# PIC16LF1509 register map
Vendor: Microchip
Registers are 8-bit, read-write, no defined reset value unless marked. A register's access mark holds for its fields unless they carry their own. Addresses are absolute, and some are shared; only a register's first bit layout is shown; [hi:lo] are bit positions; {n}, {i} and the like mark numbered series.

## SFR
0x00 INDF0 — (power-on value xxxxxxxx)
0x01 INDF1 — (power-on value xxxxxxxx)
0x02 PCL reset 0x0
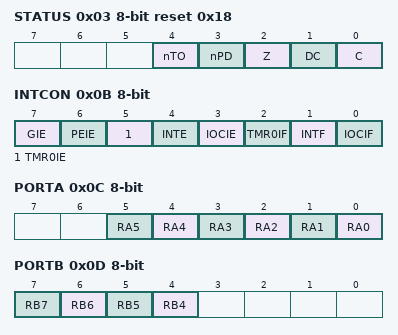
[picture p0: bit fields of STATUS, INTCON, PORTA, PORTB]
0x03 STATUS reset 0x18
  [4] nTO ro, [3] nPD ro, [2] Z, [1] DC, [0] C
0x04 FSR0L reset 0x0
0x05 FSR0H reset 0x0
0x06 FSR1L reset 0x0
0x07 FSR1H reset 0x0
0x08 BSR reset 0x0
  [4:0] BSR
0x09 WREG reset 0x0
  [7:0] WREG0
0x0A PCLATH reset 0x0
  [6:0] PCLATH
0x0B INTCON — (power-on value 0000000x)
  [7] GIE, [6] PEIE, [5] TMR0IE, [4] INTE, [3] IOCIE, [2] TMR0IF, [1] INTF, [0] IOCIF ro
0x0C PORTA — (power-on value --xxxxxx)
  [n] RA{n} (n=0..5)
0x0D PORTB — (power-on value xxxx----)
  [n] RB{n} (n=4..7)
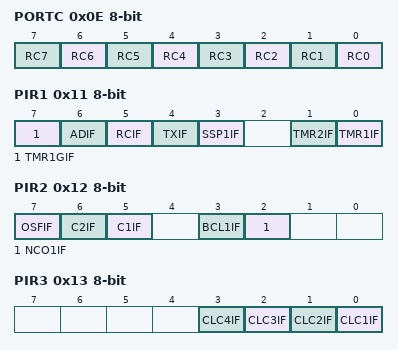
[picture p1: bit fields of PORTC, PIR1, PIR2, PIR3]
0x0E PORTC — (power-on value xxxxxxxx)
  [n] RC{n} (n=0..7)
0x11 PIR1 — (power-on value 00xx0-00)
  [7] TMR1GIF — Timer1 Gate Interrupt Flag bit
  [6] ADIF — A/D Converter Interrupt Flag bit
  [5] RCIF — EUSART Receive Interrupt Enable bit
  [4] TXIF — EUSART Transmit Interrupt Enable bit
  [3] SSP1IF — Synchronous Serial Port (MSSP) Interrupt Flag bit
  [1] TMR2IF — TMR2 to PR2 Match Interrupt Flag bit
  [0] TMR1IF — TMR1 Overflow Interrupt Flag bit
0x12 PIR2 — (power-on value x00-00--)
  [7] OSFIF — Oscillator Fail Interrupt Enable bit
  [6] C2IF — Numerically Controlled Oscillator Flag bit
  [5] C1IF — Numerically Controlled Oscillator Flag bit
  [3] BCL1IF — MSSP Bus Collision Interrupt Flag bit
  [2] NCO1IF — Numerically Controlled Oscillator Flag bit
0x13 PIR3 — (power-on value ----xx00)
  [n-1] CLC{n}IF (n=1..4) — Configurable Logic Block Interrupt Flag
0x15 TMR0 — (power-on value xxxxxxxx)
0x16 TMR1L — (power-on value xxxxxxxx)
0x17 TMR1H — (power-on value xxxxxxxx)
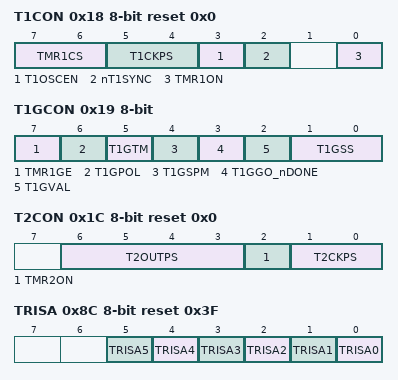
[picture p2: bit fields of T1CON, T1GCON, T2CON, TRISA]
0x18 T1CON reset 0x0
  [7:6] TMR1CS, [5:4] T1CKPS, [3] T1OSCEN, [2] nT1SYNC, [0] TMR1ON
0x19 T1GCON — (power-on value 00000x00)
  [7] TMR1GE, [6] T1GPOL, [5] T1GTM, [4] T1GSPM, [3] T1GGO_nDONE, [2] T1GVAL ro, [1:0] T1GSS
0x1A TMR2 reset 0x0
0x1B PR2 reset 0xFF
0x1C T2CON reset 0x0
  [6:3] T2OUTPS, [2] TMR2ON, [1:0] T2CKPS
0x8C TRISA reset 0x3F — PORTA Data Direction Control Register
  [n] TRISA{n} (n=0..5)
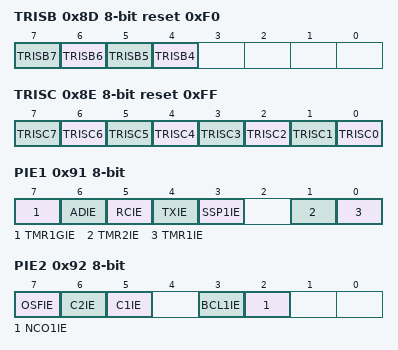
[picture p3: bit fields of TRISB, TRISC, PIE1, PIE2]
0x8D TRISB reset 0xF0
  [n] TRISB{n} (n=4..7)
0x8E TRISC reset 0xFF — PORTC Data Direction Control Register
  [n] TRISC{n} (n=0..7)
0x91 PIE1 — Peripheral Interrupt Enable Register 1 (power-on value 00xx0-00)
  [7] TMR1GIE — Timer1 Gate Interrupt Enable bit
  [6] ADIE — A/D Converter Interrupt Enable bit
  [5] RCIE
  [4] TXIE
  [3] SSP1IE
  [1] TMR2IE — TMR2 to PR2 Match Interrupt Enable bit
  [0] TMR1IE — TMR1 Overflow Interrupt Enable bit
0x92 PIE2 — Peripheral Interrupt Enable Register 2 (power-on value x00-00--)
  [7] OSFIE, [6] C2IE, [5] C1IE, [3] BCL1IE, [2] NCO1IE
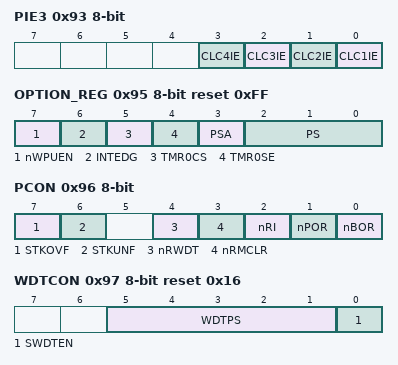
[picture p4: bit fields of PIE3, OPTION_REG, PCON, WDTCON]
0x93 PIE3 — Peripheral Interrupt Enable Register 3 (power-on value ----xx00)
  [n-1] CLC{n}IE (n=1..4)
0x95 OPTION_REG reset 0xFF — Option Register
  [7] nWPUEN — Weak Pull-up Enable bit
  [6] INTEDG — Interrupt Edge Select bit
  [5] TMR0CS
  [4] TMR0SE — TMR0 Source Edge Select bit
  [3] PSA — Prescaler Active bit
  [2:0] PS
0x96 PCON — Power Control Register (power-on value 00-111qq)
  [7] STKOVF — Stack Overflow Flag bit
  [6] STKUNF — Stack Underflow Flag bit
  [4] nRWDT
  [3] nRMCLR — MCLR Reset Flag bit
  [2] nRI — RESET Instruction Flag bit
  [1] nPOR — Power-on Reset Status bit
  [0] nBOR — Brown-out Reset Status bit
0x97 WDTCON reset 0x16 — Watchdog Timer Control Register
  [5:1] WDTPS
  [0] SWDTEN — Software Enable/Disable for Watch Dog Timer bit
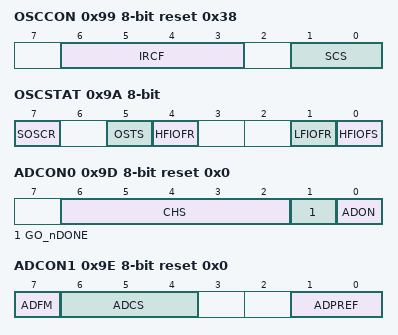
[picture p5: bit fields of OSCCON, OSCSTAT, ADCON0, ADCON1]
0x99 OSCCON reset 0x38 — Oscillator Control Register
  [6:3] IRCF, [1:0] SCS
0x9A OSCSTAT ro — Oscillator Status Register (power-on value 0-q0--00)
  [7] SOSCR
  [5] OSTS — Oscillator Start-up Time-out Status bit
  [4] HFIOFR
  [1] LFIOFR — Low Freqency Internal Oscillator Ready bit
  [0] HFIOFS — Low Freqency Internal Oscillator Ready bit
0x9B ADRESL — A/D Result Register LSB (power-on value xxxxxxxx)
0x9C ADRESH — A/D Result Register MSB (power-on value xxxxxxxx)
0x9D ADCON0 reset 0x0 — Analog-to-Digital Control Register 0
  [6:2] CHS
  [1] GO_nDONE — A/D Conversion Status bit
  [0] ADON — A/D Module Enable bit
0x9E ADCON1 reset 0x0 — Analog-to-Digital Control Register 1
  [7] ADFM — A/D Result Format Select bit
  [6:4] ADCS
  [1:0] ADPREF
0x9F ADCON2 reset 0x0 — Analog-to-Digital Control Register 2
  [7:4] TRIGSEL
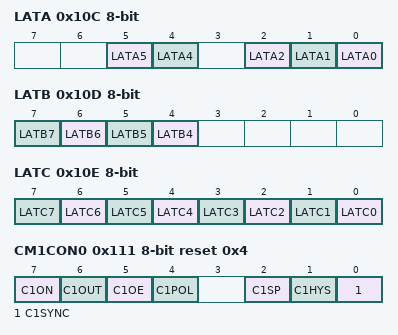
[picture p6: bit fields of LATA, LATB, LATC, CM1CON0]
0x10C LATA — (power-on value --xx-xxx)
  [5] LATA5, [4] LATA4, [2] LATA2, [1] LATA1, [0] LATA0
0x10D LATB — (power-on value xxxx----)
  [n] LATB{n} (n=4..7)
0x10E LATC — (power-on value xxxxxxxx)
  [n] LATC{n} (n=0..7)
0x111 CM1CON0 reset 0x4
  [7] C1ON — Comparator Enable bit
  [6] C1OUT ro — Comparator Output bit
  [5] C1OE — Comparator Output Enable bit
  [4] C1POL — Comparator Output Polarity Select bit
  [2] C1SP — Comparator Speed/Power Select bit
  [1] C1HYS — Comparator Hysteresis Enable bit
  [0] C1SYNC — Comparator Output Synchronous Mode bit
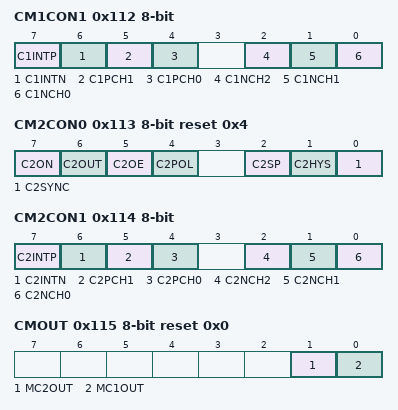
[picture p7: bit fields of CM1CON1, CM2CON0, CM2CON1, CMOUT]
0x112 CM1CON1 — (power-on value 0000-x00)
  [7] C1INTP — Comparator Interrupt on Positive going edge Enable bits
  [6] C1INTN — Comparator Interrupt on Negative going edge Enable bits
  [5] C1PCH1 — Comparator Positive Input Channel Select bits
  [4] C1PCH0 — Comparator Positive Input Channel Select bits
  [2] C1NCH2
  [1] C1NCH1 — Comparator Negative Input Channel Select bits
  [0] C1NCH0 — Comparator Negative Input Channel Select bits
0x113 CM2CON0 reset 0x4
  [7] C2ON, [6] C2OUT ro, [5] C2OE, [4] C2POL, [2] C2SP, [1] C2HYS, [0] C2SYNC
0x114 CM2CON1 — (power-on value 0000-x00)
  [7] C2INTP — Comparator Interrupt on Positive going edge Enable bits
  [6] C2INTN — Comparator Interrupt on Negative going edge Enable bits
  [5] C2PCH1 — Comparator Positive Input Channel Select bits
  [4] C2PCH0 — Comparator Positive Input Channel Select bits
  [2] C2NCH2
  [1] C2NCH1 — Comparator Negative Input Channel Select bits
  [0] C2NCH0 — Comparator Negative Input Channel Select bits
0x115 CMOUT ro reset 0x0 — Comparator Output Register
  [1] MC2OUT, [0] MC1OUT
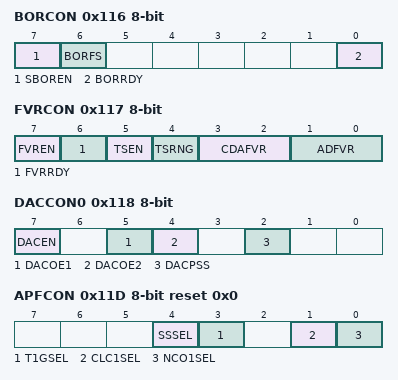
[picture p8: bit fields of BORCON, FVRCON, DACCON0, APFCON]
0x116 BORCON — Brown-out Reset Control Register (power-on value 10-----q)
  [7] SBOREN — Software Brown Out Reset Enable bit
  [6] BORFS
  [0] BORRDY ro — Brown-out Reset Circuit Ready Status bit
0x117 FVRCON — Voltage Reference Control Register 0 (power-on value 0q00xx00)
  [7] FVREN — Fixed Voltage Reference Enable
  [6] FVRRDY ro — Fixed Voltage Reference Ready Flag
  [5] TSEN — Temperature Sensor Enable
  [4] TSRNG — Temperature Sensor Range Select
  [3:2] CDAFVR
  [1:0] ADFVR — A/D Converter Fixed Voltage Reference Selection
0x118 DACCON0 — Voltage Reference Control Register 0 (power-on value 0-xx-x--)
  [7] DACEN — DAC 1 Enable bit
  [5] DACOE1
  [4] DACOE2
  [2] DACPSS
0x119 DACCON1 — Voltage Reference Control Register 1 (power-on value ---xxxxx)
  [4:0] DACR
0x11D APFCON reset 0x0 — Alternate Pin Function Control Register
  [4] SSSEL, [3] T1GSEL, [1] CLC1SEL, [0] NCO1SEL
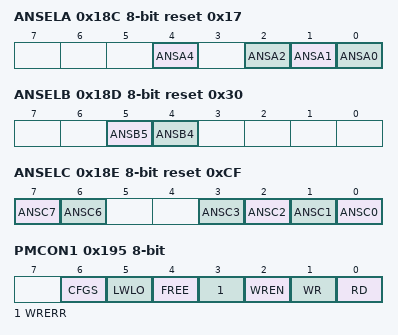
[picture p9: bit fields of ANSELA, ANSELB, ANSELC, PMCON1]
0x18C ANSELA reset 0x17
  [4] ANSA4, [2] ANSA2, [1] ANSA1, [0] ANSA0
0x18D ANSELB reset 0x30
  [5] ANSB5, [4] ANSB4
0x18E ANSELC reset 0xCF
  [7] ANSC7, [6] ANSC6, [n] ANSC{n} (n=0..3)
0x191 PMADRL reset 0x0
0x192 PMADRH reset 0x80
  [6:0] PMADRH
0x193 PMDATL — (power-on value xxxxxxxx)
0x194 PMDATH — (power-on value --xxxxxx)
  [5:0] PMDATH
0x195 PMCON1 — (power-on value 1000x000)
  [6] CFGS — FLASH Program / Configuration Select bit
  [5] LWLO — Load Write Latches Only bit
  [4] FREE — Program FLASH Erase Enable bit
  [3] WRERR — Sequence Error Flag bit
  [2] WREN — Program/Erase Enable bit
  [1] WR — Write Control bit (can only be set)
  [0] RD — Read Control bit (can only be set)
0x196 PMCON2 wo reset 0x0
0x199 RCREG — (power-on value xxxxxxxx)
0x19A TXREG — (power-on value xxxxxxxx)
0x19B SPBRGL — (power-on value xxxxxxxx)
0x19C SPBRGH — (power-on value xxxxxxxx)
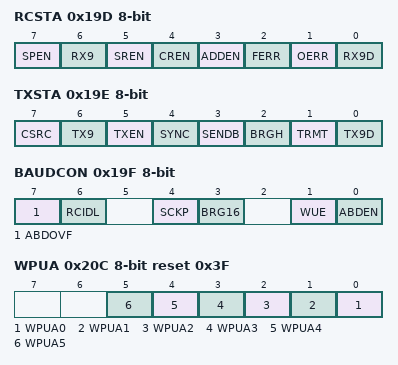
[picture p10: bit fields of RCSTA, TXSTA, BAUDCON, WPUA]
0x19D RCSTA — (power-on value xxxxxxxx)
  [7] SPEN, [6] RX9, [5] SREN, [4] CREN, [3] ADDEN, [2] FERR ro, [1] OERR ro, [0] RX9D ro
0x19E TXSTA — Transmit Status and Control Register (power-on value xxxxxxxx)
  [7] CSRC, [6] TX9, [5] TXEN, [4] SYNC, [3] SENDB, [2] BRGH, [1] TRMT ro, [0] TX9D
0x19F BAUDCON — Baud Rate Control Register (power-on value xx-xx-xx)
  [7] ABDOVF ro, [6] RCIDL ro, [4] SCKP, [3] BRG16, [1] WUE, [0] ABDEN
0x20C WPUA reset 0x3F
  [n] WPUA{n} (n=0..5)
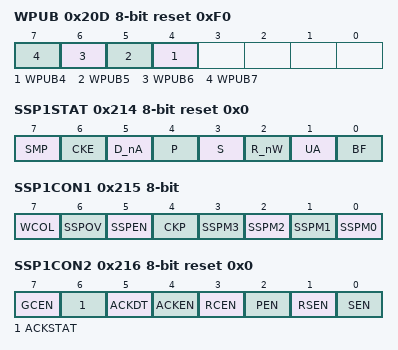
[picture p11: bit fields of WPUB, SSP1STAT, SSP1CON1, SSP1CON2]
0x20D WPUB reset 0xF0
  [n] WPUB{n} (n=4..7)
0x211 SSP1BUF — (power-on value xxxxxxxx)
  [7:0] SSPBUF
0x212 SSP1ADD reset 0x0
  [7:0] ADD
0x213 SSP1MSK reset 0xFF
  [7:0] MSK
0x214 SSP1STAT reset 0x0
  [7] SMP, [6] CKE, [5] D_nA, [4] P, [3] S, [2] R_nW, [1] UA, [0] BF
0x215 SSP1CON1 — (power-on value 0000xxxx)
  [7] WCOL, [6] SSPOV, [5] SSPEN, [4] CKP, [n] SSPM{n} (n=0..3)
0x216 SSP1CON2 reset 0x0
  [7] GCEN, [6] ACKSTAT, [5] ACKDT, [4] ACKEN, [3] RCEN, [2] PEN, [1] RSEN, [0] SEN
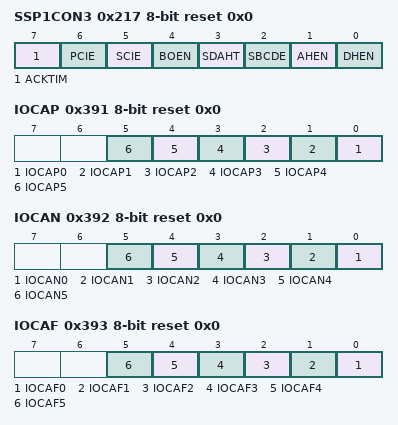
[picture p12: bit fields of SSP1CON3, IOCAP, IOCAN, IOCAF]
0x217 SSP1CON3 reset 0x0
  [7] ACKTIM, [6] PCIE, [5] SCIE, [4] BOEN, [3] SDAHT, [2] SBCDE, [1] AHEN, [0] DHEN
0x391 IOCAP reset 0x0
  [n] IOCAP{n} (n=0..5)
0x392 IOCAN reset 0x0
  [n] IOCAN{n} (n=0..5)
0x393 IOCAF reset 0x0
  [n] IOCAF{n} (n=0..5)
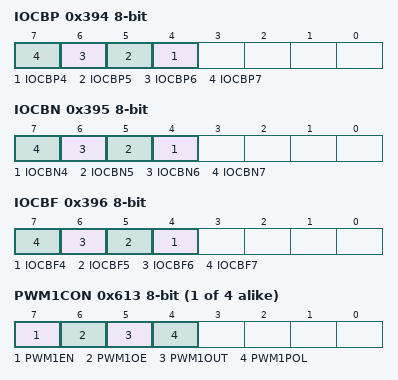
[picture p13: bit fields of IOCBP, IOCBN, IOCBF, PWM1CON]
0x394 IOCBP — Interrupt-On-Change Positive Edge Register (power-on value xxxx----)
  [n] IOCBP{n} (n=4..7)
0x395 IOCBN — Interrupt-On-Change Negative Edge Register (power-on value xxxx----)
  [n] IOCBN{n} (n=4..7)
0x396 IOCBF — (power-on value xxxx----)
  [n] IOCBF{n} (n=4..7)
{0x60E+3i} PWM{i}DCL (i=1..4) — (power-on value xx------)
  [7:6] PWM{i}DCL
{0x60F+3i} PWM{i}DCH (i=1..4) — (power-on value xxxxxxxx)
{0x610+3i} PWM{i}CON (i=1..4) — Configurable logic cell control (power-on value 00x0----)
  [7] PWM{i}EN, [6] PWM{i}OE, [5] PWM{i}OUT ro, [4] PWM{i}POL
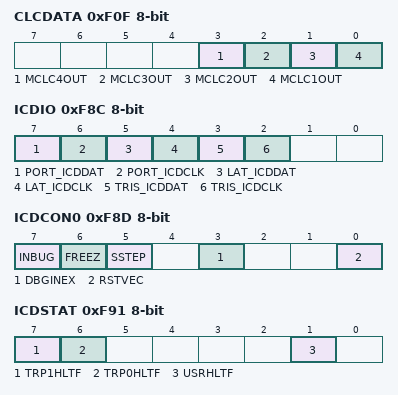
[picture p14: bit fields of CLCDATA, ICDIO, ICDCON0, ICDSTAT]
0xF0F CLCDATA — (power-on value ----xx00)
  [3] MCLC4OUT, [2] MCLC3OUT, [1] MCLC2OUT ro, [0] MCLC1OUT ro
0xF8C ICDIO — (power-on value xxxxxx--)
  [7] PORT_ICDDAT, [6] PORT_ICDCLK, [5] LAT_ICDDAT, [4] LAT_ICDCLK, [3] TRIS_ICDDAT, [2] TRIS_ICDCLK
0xF8D ICDCON0 — (power-on value xxx-x--x)
  [7] INBUG, [6] FREEZ, [5] SSTEP, [3] DBGINEX, [0] RSTVEC
0xF91 ICDSTAT — (power-on value xx----x-)
  [7] TRP1HLTF, [6] TRP0HLTF, [1] USRHLTF
0xF95 DEVSEL — (power-on value -----xxx)
  [2] DEVSEL2, [1] DEVSEL1, [0] DEVSEL0
0xF96 ICDINSTL — (power-on value xxxxxxxx)
  [n] DBGIN{n} (n=0..7)
0xF97 ICDINSTH — (power-on value --xxxxxx)
  [n-8] DBGIN{n} (n=8..13)
0xF9C ICDBK0CON — (power-on value x------x)
  [7] BKEN, [0] BKHLT
0xF9D ICDBK0L — (power-on value xxxxxxxx)
  [n] BKA{n} (n=0..7)
0xF9E ICDBK0H — (power-on value -xxxxxxx)
  [n-8] BKA{n} (n=8..14)
0xFE3 BSRICDSHAD — (power-on value ---xxxxx)
  [4:0] BSR_ICDSHAD
0xFE4 STATUS_SHAD — (power-on value -----xxx)
  [2] Z_SHAD, [1] DC_SHAD, [0] C_SHAD
0xFE5 WREG_SHAD — (power-on value xxxxxxxx)
0xFE6 BSR_SHAD — (power-on value ---xxxxx)
  [4:0] BSR_SHAD
0xFE7 PCLATH_SHAD — (power-on value -xxxxxxx)
  [6:0] PCLATH_SHAD
0xFE8 FSR0L_SHAD — (power-on value xxxxxxxx)
0xFE9 FSR0H_SHAD — (power-on value xxxxxxxx)
0xFEA FSR1L_SHAD — (power-on value xxxxxxxx)
0xFEB FSR1H_SHAD — (power-on value xxxxxxxx)
0xFED STKPTR — Current Stack pointer (power-on value ---xxxxx)
  [4:0] STKPTR
0xFEE TOSL — Top of Stack Low byte (power-on value xxxxxxxx)
0xFEF TOSH — Top of Stack High byte (power-on value -xxxxxxx)
  [6:0] TOSH
